# STM32L443xx register map
File version: 1.0
Registers are 32-bit, read-write, reset 0x0 unless marked. A register's access mark holds for its fields unless they carry their own. Offsets are from the block's base; [hi:lo] are bit positions.

## OPAMP — Operational Amplifier (OPAMP)
Base 0x40007800
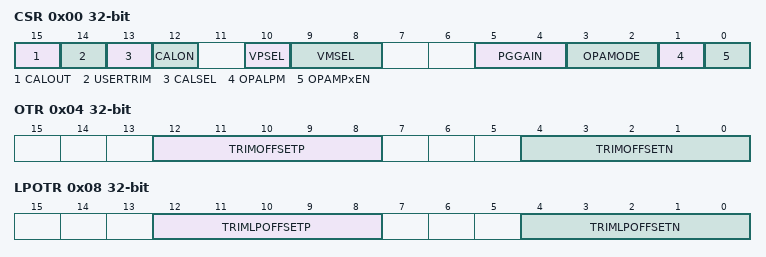
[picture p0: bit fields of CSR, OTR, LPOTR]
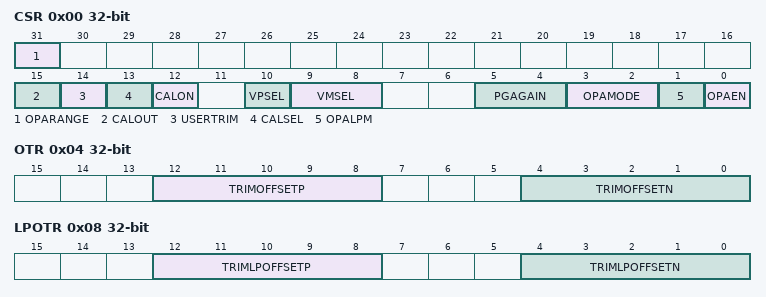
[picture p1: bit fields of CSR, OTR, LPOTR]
0x00 CSR — OPAMP control/status register
  [15] CALOUT — Operational amplifier1 calibration output
  [14] USERTRIM — User trimming enable
    0=FACTORY (OPAMP trimming factors set to factory values); 1=USER (OPAMP trimming factors set to user values)
  [13] CALSEL — Calibration selection
  [12] CALON — Calibration mode enable
    0=FUNCTIONAL (OPAMP functional mode); 1=CALIBRATION (OPAMP calibration mode)
  [10] VPSEL — Non inverted input selection
    0=NONINVERT_IO0 (OPAMP non inverting input connected to GPIO pin (pin PA0 for OPAMP1, pin PA6 for OPAMP2)); 1=NONINV_DAC1_CH1 (OPAMP non inverting input connected to DAC1 channel1 output)
  [9:8] VMSEL — Inverting input selection
    0=IO0 (OPAMP inverting input connected to GPIO pin (valid also in PGA mode for filtering). Note: OPAMP inverting input is used with OPAMP in mode standalone or PGA with external capacitors for filtering circuit. Otherwise (OPAMP in mode follower), OPAMP inverting input is not used (not connected to GPIO pin).); 1=IO1 (OPAMP inverting input (low leakage input) connected to GPIO pin (available only on package BGA132). Note: OPAMP inverting input is used with OPAMP in mode standalone or PGA with external capacitors for filtering circuit. Otherwise (OPAMP in mode follower), OPAMP inverting input is not used (not connected to GPIO pin).); 2=CONNECT_NO (OPAMP inverting input not externally connected (intended for OPAMP in mode follower or PGA without external capacitors for filtering))
  [5:4] PGGAIN — Operational amplifier Programmable amplifier gain value
    0=GAIN_2 (OPAMP PGA gain 2); 1=GAIN_4 (OPAMP PGA gain 4); 2=GAIN_8 (OPAMP PGA gain 8); 3=GAIN_16 (OPAMP PGA gain 16)
  [3:2] OPAMODE — Operational amplifier PGA mode
    0=STANDALONE (OPAMP functional mode, OPAMP operation in standalone); 3=FOLLOWER (OPAMP functional mode, OPAMP operation in follower); 2=PGA (OPAMP functional mode, OPAMP operation in PGA)
  [1] OPALPM — Operational amplifier Low Power Mode
  [0] OPAMPxEN — OPAMP enable
0x04 OTR — OPAMP
  [12:8] TRIMOFFSETP — Trim for PMOS differential pairs
  [4:0] TRIMOFFSETN — Trim for NMOS differential pairs
0x08 LPOTR — OPAMP
  [12:8] TRIMLPOFFSETP — Trim for PMOS differential pairs
  [4:0] TRIMLPOFFSETN — Trim for NMOS differential pairs

## OPAMP1 — Operational Amplifier (OPAMP)
Base 0x40007800; alternate view of OPAMP
0x00 CSR — OPAMP control/status register
  [31] OPARANGE — Common to several OPAMP instances: Operational amplifier voltage supply range. Bit intended to be used with OPAMP common instance (OPAMP_Common_TypeDef)
    0=LOW (Power supply range low. On STM32L4 series: Vdda lower than 2.4V.); 1=HIGH (Power supply range high. On STM32L4 series: Vdda higher than 2.4V.)
  [15] CALOUT — Operational amplifier1 calibration output
  [14] USERTRIM — User trimming enable
  [13] CALSEL — Calibration selection
  [12] CALON — Calibration mode enable
  [10] VPSEL — Non inverted input selection
  [9:8] VMSEL — Inverting input selection
  [5:4] PGAGAIN — Operational amplifier1 Programmable amplifier gain value
  [3:2] OPAMODE — Operational amplifier1 PGA mode
  [1] OPALPM — Operational amplifier1 Low Power Mode
  [0] OPAEN — Operational amplifier1 Enable
0x04 OTR — OPAMP
  [12:8] TRIMOFFSETP — Trim for PMOS differential pairs
  [4:0] TRIMOFFSETN — Trim for NMOS differential pairs
0x08 LPOTR — OPAMP
  [12:8] TRIMLPOFFSETP — Trim for PMOS differential pairs
  [4:0] TRIMLPOFFSETN — Trim for NMOS differential pairs

## SWPMI1 — Single Wire Protocol Master Interface SPWMI
Base 0x40008800
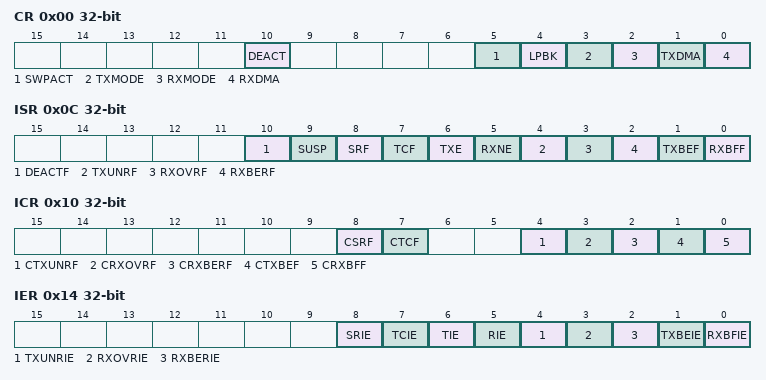
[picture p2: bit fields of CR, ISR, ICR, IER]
0x00 CR — SWPMI Configuration/Control register
  [10] DEACT — Single wire protocol master interface deactivate
  [5] SWPACT — Single wire protocol master interface activate
  [4] LPBK — Loopback mode enable
  [3] TXMODE — Transmission buffering mode
    0=SINGLE (Single software buffer mode for transmission); 1=MULTI (Multi software buffermode for transmission)
  [2] RXMODE — Reception buffering mode
    0=SINGLE (Single software buffer mode for reception); 1=MULTI (Multi software buffermode for reception)
  [1] TXDMA — Transmission DMA enable
  [0] RXDMA — Reception DMA enable
0x04 BRR — SWPMI bitrate register
  [5:0] BR — BR[5:0] bits (Bitrate prescaler)
0x0C ISR — SWPMI Interrupt and Status register
  [10] DEACTF — DEACTIVATED flag
  [9] SUSP — SUSPEND flag
  [8] SRF — Slave resume flag
  [7] TCF — Transfer complete flag
  [6] TXE — Transmit data register empty
  [5] RXNE — Receive data register not empty
  [4] TXUNRF — Transmit underrun error flag
  [3] RXOVRF — Receive overrun error flag
  [2] RXBERF — Receive CRC error flag
  [1] TXBEF — Transmit buffer empty flag
  [0] RXBFF — Receive buffer full flag
0x10 ICR — SWPMI Interrupt Flag Clear register
  [8] CSRF — Clear slave resume flag
  [7] CTCF — Clear transfer complete flag
  [4] CTXUNRF — Clear transmit underrun error flag
  [3] CRXOVRF — Clear receive overrun error flag
  [2] CRXBERF — Clear receive CRC error flag
  [1] CTXBEF — Clear transmit buffer empty flag
  [0] CRXBFF — Clear receive buffer full flag
0x14 IER — SWPMI Interrupt Enable register
  [8] SRIE — Slave resume interrupt enable
  [7] TCIE — Transmit complete interrupt enable
  [6] TIE — Transmit interrupt enable
  [5] RIE — Receive interrupt enable
  [4] TXUNRIE — Transmit underrun error interrupt enable
  [3] RXOVRIE — Receive overrun error interrupt enable
  [2] RXBERIE — Receive CRC error interrupt enable
  [1] TXBEIE — Transmit buffer empty interrupt enable
  [0] RXBFIE — Receive buffer full interrupt enable
0x18 RFL — SWPMI Receive Frame Length register
  [4:0] RFL — RFL[4:0] bits (Receive Frame length)
0x1C TDR — SWPMI Transmit data register
  [31:0] TD — Transmit Data Register
0x20 RDR — SWPMI Receive data register
  [31:0] RD — Receive Data Register
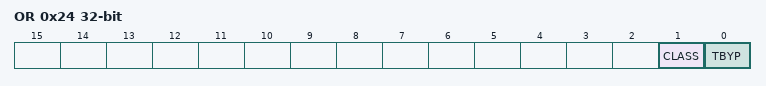
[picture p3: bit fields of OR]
0x24 OR — SWPMI Option register
  [1] CLASS — SWP Voltage Class selection
    0=C (SWPMI_IO uses directly VDD voltage to operate in class C); 1=B (SWPMI_IO uses an internal voltage regulator to operate in class B)
  [0] TBYP — SWP Transceiver Bypass
